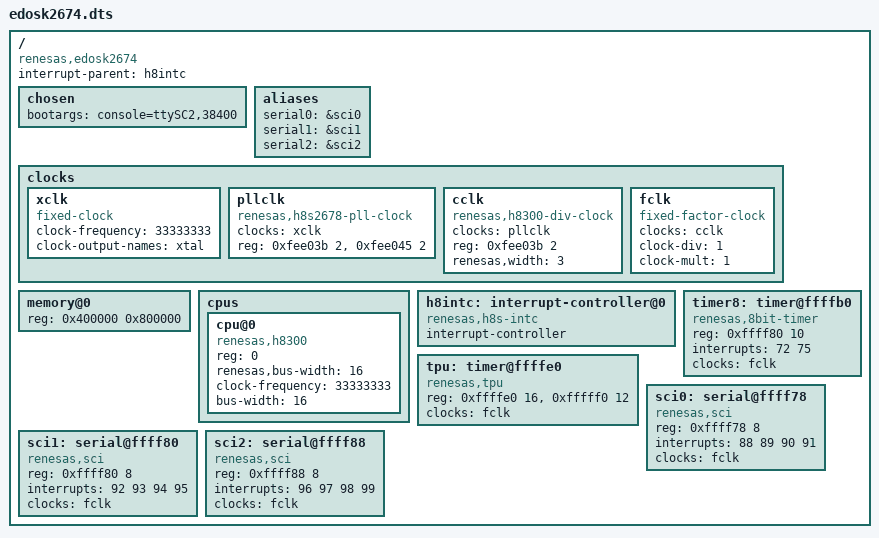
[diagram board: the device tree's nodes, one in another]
#include <dt-bindings/clock/renesas,8bit-timer.h>

/dts-v1/;
/ {
	compatible = "renesas,edosk2674";
	#address-cells = <1>;
	#size-cells = <1>;
	interrupt-parent = <&h8intc>;

	chosen {
		bootargs = "console=ttySC2,38400";
	};
	aliases {
		serial0 = &sci0;
		serial1 = &sci1;
		serial2 = &sci2;
	};

	clocks {
		ranges;
		#address-cells = <1>;
		#size-cells = <1>;
		xclk: xclk {
			#clock-cells = <0>;
			compatible = "fixed-clock";
			clock-frequency = <33333333>;
			clock-output-names = "xtal";
		};
		pllclk: pllclk {
			compatible = "renesas,h8s2678-pll-clock";
			clocks = <&xclk>;
			#clock-cells = <0>;
			reg = <0xfee03b 2>, <0xfee045 2>;
		};
		cclk: cclk {
			compatible = "renesas,h8300-div-clock";
			clocks = <&pllclk>;
			#clock-cells = <0>;
			reg = <0xfee03b 2>;
			renesas,width = <3>;
		};
		fclk: fclk {
			compatible = "fixed-factor-clock";
			clocks = <&cclk>;
			#clock-cells = <0>;
			clock-div = <1>;
			clock-mult = <1>;
		};
	};

	memory@0 {
		device_type = "memory";
		reg = <0x400000 0x800000>;
	};

	cpus {
		#address-cells = <1>;
		#size-cells = <0>;
		cpu@0 {
			compatible = "renesas,h8300";
			reg = <0>;
			renesas,bus-width = <16>;
			clock-frequency = <33333333>;
			bus-width = <16>;
		};
	};

	h8intc: interrupt-controller@0 {
		compatible = "renesas,h8s-intc", "renesas,h8300-intc";
		#interrupt-cells = <1>;
		interrupt-controller;
	};
	tpu: timer@ffffe0 {
		compatible = "renesas,tpu";
		reg = <0xffffe0 16>, <0xfffff0 12>;
		clocks = <&fclk>;
		clock-names = "fck";
	};

	timer8: timer@ffffb0 {
		compatible = "renesas,8bit-timer";
		reg = <0xffff80 10>;
		interrupts = <72 75>;
		clocks = <&fclk>;
		clock-names = "fck";
	};

	sci0: serial@ffff78 {
		compatible = "renesas,sci";
		reg = <0xffff78 8>;
		interrupts = <88 89 90 91>;
		clocks = <&fclk>;
		clock-names = "sci_ick";
	};
	sci1: serial@ffff80 {
		compatible = "renesas,sci";
		reg = <0xffff80 8>;
		interrupts = <92 93 94 95>;
		clocks = <&fclk>;
		clock-names = "sci_ick";
	};
	sci2: serial@ffff88 {
		compatible = "renesas,sci";
		reg = <0xffff88 8>;
		interrupts = <96 97 98 99>;
		clocks = <&fclk>;
		clock-names = "sci_ick";
	};
};
